AUTOSAR XML (schema 4-3-0)
package /ComponentTypes
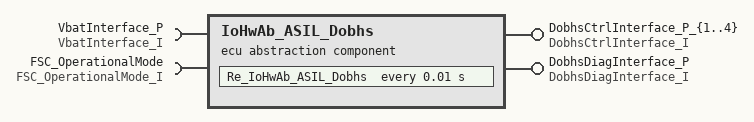
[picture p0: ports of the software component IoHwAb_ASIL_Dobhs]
  ecu abstraction sw component type IoHwAb_ASIL_Dobhs
    5 x provide port:
      DobhsCtrlInterface_P_{1..4}: provided-com-specs=[{operation=SetDobhsActive, queue-length=1}, {operation=GetDobhsPinState, queue-length=1}], provided-interface=DobhsCtrlInterface_I
      DobhsDiagInterface_P: server-com-spec{operation=IoHwAbOperation, queue-length=1}, provided-interface=DobhsDiagInterface_I
    require port VbatInterface_P: required-interface=VbatInterface_I
      required-com-specs:
        DobhsCtrlInterface_P_4
        DobhsCtrlInterface_P_5
        DobhsCtrlInterface_P_3
        DobhsCtrlInterface_P_2
        DobhsCtrlInterface_P_1
        FSC_OperationalMode
        VbatInterface_P
    require port FSC_OperationalMode: required-com-specs=[FSC_OperationalMode, VbatInterface_P], required-interface=FSC_OperationalMode_I
    behavior IoHwAb_ASIL_Dobhs_InternalBehavior
      timing event TMT_IoHwAb_ASIL_Dobhs: start-on-event=Re_IoHwAb_ASIL_Dobhs, period=0.01
      runnable Re_IoHwAb_ASIL_Dobhs: symbol=IoHwAb_ASIL_Dobhs
  swc implementation IoHwAb_ASIL_Dobhs_Implementation: behavior=IoHwAb_ASIL_Dobhs_InternalBehavior
